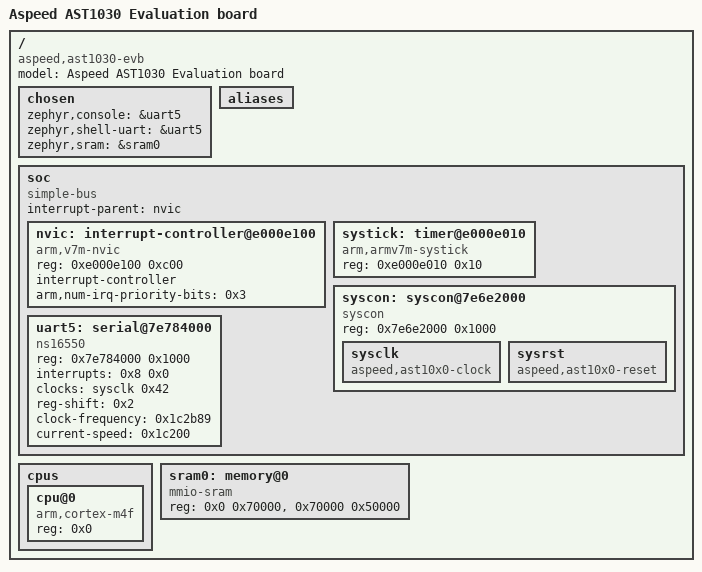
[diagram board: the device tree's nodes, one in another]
/dts-v1/;

/* node '/' defined in zephyr/dts/common/skeleton.dtsi:9 */
/ {
	#address-cells = < 0x1 >;                  /* in zephyr/dts/common/skeleton.dtsi:10 */
	#size-cells = < 0x1 >;                     /* in zephyr/dts/common/skeleton.dtsi:11 */
	model = "Aspeed AST1030 Evaluation board"; /* in zephyr/boards/aspeed/ast1030_evb/ast1030_evb.dts:11 */
	compatible = "aspeed,ast1030-evb";         /* in zephyr/boards/aspeed/ast1030_evb/ast1030_evb.dts:12 */

	/* node '/chosen' defined in zephyr/dts/common/skeleton.dtsi:13 */
	chosen {
		zephyr,console = &uart5;    /* in zephyr/boards/aspeed/ast1030_evb/ast1030_evb.dts:15 */
		zephyr,shell-uart = &uart5; /* in zephyr/boards/aspeed/ast1030_evb/ast1030_evb.dts:16 */
		zephyr,sram = &sram0;       /* in zephyr/boards/aspeed/ast1030_evb/ast1030_evb.dts:17 */
	};

	/* node '/aliases' defined in zephyr/dts/common/skeleton.dtsi:15 */
	aliases {
	};

	/* node '/soc' defined in zephyr/dts/arm/armv7-m.dtsi:6 */
	soc {
		#address-cells = < 0x1 >;     /* in zephyr/dts/arm/armv7-m.dtsi:7 */
		#size-cells = < 0x1 >;        /* in zephyr/dts/arm/armv7-m.dtsi:8 */
		compatible = "simple-bus";    /* in zephyr/dts/arm/armv7-m.dtsi:9 */
		interrupt-parent = < &nvic >; /* in zephyr/dts/arm/armv7-m.dtsi:10 */
		ranges;                       /* in zephyr/dts/arm/armv7-m.dtsi:11 */

		/* node '/soc/interrupt-controller@e000e100' defined in zephyr/dts/arm/armv7-m.dtsi:13 */
		nvic: interrupt-controller@e000e100 {
			#address-cells = < 0x1 >;            /* in zephyr/dts/arm/armv7-m.dtsi:14 */
			compatible = "arm,v7m-nvic";         /* in zephyr/dts/arm/armv7-m.dtsi:15 */
			reg = < 0xe000e100 0xc00 >;          /* in zephyr/dts/arm/armv7-m.dtsi:16 */
			interrupt-controller;                /* in zephyr/dts/arm/armv7-m.dtsi:17 */
			#interrupt-cells = < 0x2 >;          /* in zephyr/dts/arm/armv7-m.dtsi:18 */
			arm,num-irq-priority-bits = < 0x3 >; /* in zephyr/dts/arm/aspeed/ast10x0.dtsi:55 */
			phandle = < 0x1 >;                   /* in zephyr/dts/arm/armv7-m.dtsi:10 */
		};

		/* node '/soc/timer@e000e010' defined in zephyr/dts/arm/armv7-m.dtsi:21 */
		systick: timer@e000e010 {
			compatible = "arm,armv7m-systick"; /* in zephyr/dts/arm/armv7-m.dtsi:22 */
			reg = < 0xe000e010 0x10 >;         /* in zephyr/dts/arm/armv7-m.dtsi:23 */
		};

		/* node '/soc/syscon@7e6e2000' defined in zephyr/dts/arm/aspeed/ast10x0.dtsi:28 */
		syscon: syscon@7e6e2000 {
			compatible = "syscon";       /* in zephyr/dts/arm/aspeed/ast10x0.dtsi:29 */
			reg = < 0x7e6e2000 0x1000 >; /* in zephyr/dts/arm/aspeed/ast10x0.dtsi:30 */

			/* node '/soc/syscon@7e6e2000/sysclk' defined in zephyr/dts/arm/aspeed/ast10x0.dtsi:32 */
			sysclk: sysclk {
				compatible = "aspeed,ast10x0-clock"; /* in zephyr/dts/arm/aspeed/ast10x0.dtsi:33 */
				#clock-cells = < 0x1 >;              /* in zephyr/dts/arm/aspeed/ast10x0.dtsi:34 */
				phandle = < 0x2 >;                   /* in zephyr/dts/arm/aspeed/ast10x0.dtsi:47 */
			};

			/* node '/soc/syscon@7e6e2000/sysrst' defined in zephyr/dts/arm/aspeed/ast10x0.dtsi:37 */
			sysrst: sysrst {
				compatible = "aspeed,ast10x0-reset"; /* in zephyr/dts/arm/aspeed/ast10x0.dtsi:38 */
				#reset-cells = < 0x1 >;              /* in zephyr/dts/arm/aspeed/ast10x0.dtsi:39 */
			};
		};

		/* node '/soc/serial@7e784000' defined in zephyr/dts/arm/aspeed/ast10x0.dtsi:43 */
		uart5: serial@7e784000 {
			compatible = "ns16550";         /* in zephyr/dts/arm/aspeed/ast10x0.dtsi:44 */
			reg = < 0x7e784000 0x1000 >;    /* in zephyr/dts/arm/aspeed/ast10x0.dtsi:45 */
			interrupts = < 0x8 0x0 >;       /* in zephyr/dts/arm/aspeed/ast10x0.dtsi:46 */
			clocks = < &sysclk 0x42 >;      /* in zephyr/dts/arm/aspeed/ast10x0.dtsi:47 */
			reg-shift = < 0x2 >;            /* in zephyr/dts/arm/aspeed/ast10x0.dtsi:49 */
			clock-frequency = < 0x1c2b89 >; /* in zephyr/boards/aspeed/ast1030_evb/ast1030_evb.dts:26 */
			current-speed = < 0x1c200 >;    /* in zephyr/boards/aspeed/ast1030_evb/ast1030_evb.dts:27 */
			status = "okay";                /* in zephyr/boards/aspeed/ast1030_evb/ast1030_evb.dts:28 */
		};
	};

	/* node '/cpus' defined in zephyr/dts/arm/aspeed/ast10x0.dtsi:12 */
	cpus {
		#address-cells = < 0x1 >; /* in zephyr/dts/arm/aspeed/ast10x0.dtsi:13 */
		#size-cells = < 0x0 >;    /* in zephyr/dts/arm/aspeed/ast10x0.dtsi:14 */

		/* node '/cpus/cpu@0' defined in zephyr/dts/arm/aspeed/ast10x0.dtsi:16 */
		cpu@0 {
			device_type = "cpu";           /* in zephyr/dts/arm/aspeed/ast10x0.dtsi:17 */
			compatible = "arm,cortex-m4f"; /* in zephyr/dts/arm/aspeed/ast10x0.dtsi:18 */
			reg = < 0x0 >;                 /* in zephyr/dts/arm/aspeed/ast10x0.dtsi:19 */
		};
	};

	/* node '/memory@0' defined in zephyr/dts/arm/aspeed/ast10x0.dtsi:23 */
	sram0: memory@0 {
		compatible = "mmio-sram";  /* in zephyr/dts/arm/aspeed/ast10x0.dtsi:24 */
		reg = < 0x0 0x70000 >,
		      < 0x70000 0x50000 >; /* in zephyr/boards/aspeed/ast1030_evb/ast1030_evb.dts:22 */
	};
};
